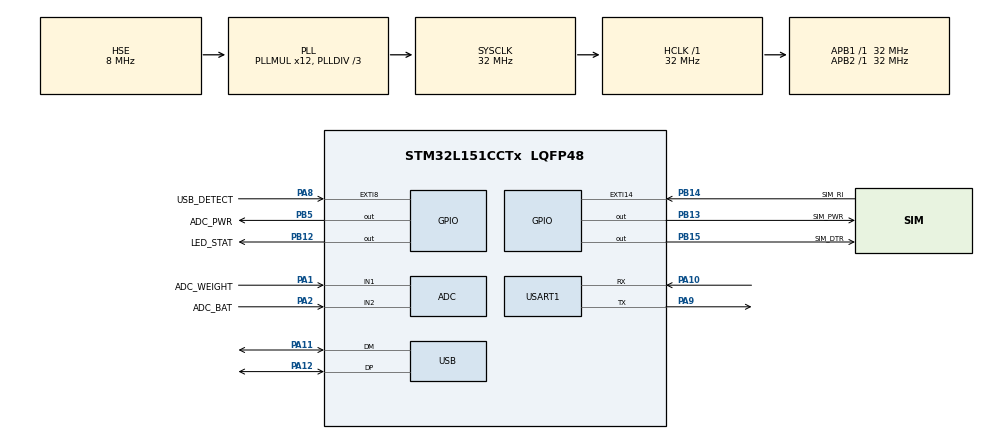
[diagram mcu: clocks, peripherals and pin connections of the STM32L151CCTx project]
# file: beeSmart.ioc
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ADC.Channel-0\#ChannelRegularConversion=ADC_CHANNEL_1
ADC.Channel-1\#ChannelRegularConversion=ADC_CHANNEL_2
ADC.ContinuousConvMode=ENABLE
ADC.NbrOfConversion=2
ADC.NbrOfConversionFlag=1
ADC.Rank-0\#ChannelRegularConversion=1
ADC.Rank-1\#ChannelRegularConversion=2
ADC.SamplingTime-0\#ChannelRegularConversion=ADC_SAMPLETIME_384CYCLES
ADC.SamplingTime-1\#ChannelRegularConversion=ADC_SAMPLETIME_384CYCLES
Dma.ADC.0.Direction=DMA_PERIPH_TO_MEMORY
Dma.ADC.0.Instance=DMA1_Channel1
Dma.ADC.0.MemDataAlignment=DMA_MDATAALIGN_HALFWORD
Dma.ADC.0.MemInc=DMA_MINC_ENABLE
Dma.ADC.0.Mode=DMA_NORMAL
Dma.ADC.0.PeriphDataAlignment=DMA_PDATAALIGN_HALFWORD
Dma.ADC.0.PeriphInc=DMA_PINC_DISABLE
Dma.ADC.0.Priority=DMA_PRIORITY_LOW
Dma.Request0=ADC
FREERTOS.Tasks01=defaultTask,0,128,StartDefaultTask,Default,NULL
Mcu.Family=STM32L1
Mcu.Name=STM32L151CCTx
Mcu.Package=LQFP48
NVIC.ADC1_IRQn=true\:5\:0\:false\:false\:true\:true\:true
NVIC.DMA1_Channel1_IRQn=true\:5\:0\:false\:false\:true\:true\:false
NVIC.EXTI15_10_IRQn=true\:5\:0\:false\:false\:true\:true\:true
NVIC.EXTI9_5_IRQn=true\:5\:0\:false\:false\:true\:true\:true
NVIC.PriorityGroup=NVIC_PRIORITYGROUP_4
NVIC.TIM2_IRQn=true\:0\:0\:false\:false\:true\:false\:false
NVIC.TimeBase=TIM2_IRQn
NVIC.TimeBaseIP=TIM2
NVIC.USART1_IRQn=true\:5\:0\:false\:false\:true\:true\:true
NVIC.USB_LP_IRQn=true\:5\:0\:false\:false\:true\:true\:false
PA1.GPIO_Label=ADC_WEIGHT
PA1.Mode=IN1
PA1.Signal=ADC_IN1
PA10.Mode=Asynchronous
PA10.Signal=USART1_RX
PA11.Mode=Device
PA11.Signal=USB_DM
PA12.Mode=Device
PA12.Signal=USB_DP
PA13.Mode=JTAG_5_pins
PA13.Signal=SYS_JTMS-SWDIO
PA14.Mode=JTAG_5_pins
PA14.Signal=SYS_JTCK-SWCLK
PA15.Mode=JTAG_5_pins
PA15.Signal=SYS_JTDI
PA2.GPIO_Label=ADC_BAT
PA2.Mode=IN2
PA2.Signal=ADC_IN2
PA8.GPIO_Label=USB_DETECT
PA8.Signal=GPXTI8
PA9.Mode=Asynchronous
PA9.Signal=USART1_TX
PB12.GPIO_Label=LED_STAT
PB12.Signal=GPIO_Output
PB13.GPIO_Label=SIM_PWR
PB13.Signal=GPIO_Output
PB14.GPIO_Label=SIM_RI
PB14.Signal=GPXTI14
PB15.GPIO_Label=SIM_DTR
PB15.Signal=GPIO_Output
PB3.Mode=JTAG_5_pins
PB3.Signal=SYS_JTDO-TRACESWO
PB4.Mode=JTAG_5_pins
PB4.Signal=SYS_JTRST
PB5.GPIO_Label=ADC_PWR
PB5.Signal=GPIO_Output
PC14-OSC32_IN.Mode=LSE-External-Oscillator
PC14-OSC32_IN.Signal=RCC_OSC32_IN
PC15-OSC32_OUT.Mode=LSE-External-Oscillator
PC15-OSC32_OUT.Signal=RCC_OSC32_OUT
PH0-OSC_IN.Mode=HSE-External-Oscillator
PH0-OSC_IN.Signal=RCC_OSC_IN
PH1-OSC_OUT.Mode=HSE-External-Oscillator
PH1-OSC_OUT.Signal=RCC_OSC_OUT
ProjectManager.HeapSize=0x200
ProjectManager.StackSize=0x400
ProjectManager.TargetToolchain=SW4STM32
RCC.48MHZClocksFreq_Value=48000000
RCC.AHBFreq_Value=32000000
RCC.APB1Freq_Value=32000000
RCC.APB1TimFreq_Value=32000000
RCC.APB2Freq_Value=32000000
RCC.APB2TimFreq_Value=32000000
RCC.HCLKFreq_Value=32000000
RCC.HSE_VALUE=8000000
RCC.HSI_VALUE=16000000
RCC.MSI_VALUE=2097000
RCC.PLLDIV=RCC_PLL_DIV3
RCC.PLLMUL=RCC_PLL_MUL12
RCC.SYSCLKFreq_VALUE=32000000
RCC.SYSCLKSource=RCC_SYSCLKSOURCE_PLLCLK
RCC.VCOOutputFreq_Value=96000000
USART1.VirtualMode=VM_ASYNC
USB_DEVICE.CLASS_NAME_FS=CDC
USB_DEVICE.VirtualMode=Cdc
USB_DEVICE.VirtualModeFS=Cdc_FS
VP_FREERTOS_VS_ENABLE.Mode=Enabled
VP_RTC_VS_RTC_Activate.Mode=RTC_Enabled
VP_RTC_VS_RTC_Calendar.Mode=RTC_Calendar
VP_RTC_VS_RTC_WakeUp_intern.Mode=WakeUp
VP_SYS_VS_tim2.Mode=TIM2
VP_USB_DEVICE_VS_USB_DEVICE_CDC_FS.Mode=CDC_FS
board=beeSmart

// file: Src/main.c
/**
  ******************************************************************************
  * File Name          : main.c
  * Description        : Main program body
  ******************************************************************************
  * This notice applies to any and all portions of this file
  * that are not between comment pairs USER CODE BEGIN and
  * USER CODE END. Other portions of this file, whether
  * inserted by the user or by software development tools
  * are owned by their respective copyright owners.
  *
  * Copyright (c) 2018 STMicroelectronics International N.V.
  * All rights reserved.
  *
  * Redistribution and use in source and binary forms, with or without
  * modification, are permitted, provided that the following conditions are met:
  *
  * 1. Redistribution of source code must retain the above copyright notice,
  *    this list of conditions and the following disclaimer.
  * 2. Redistributions in binary form must reproduce the above copyright notice,
  *    this list of conditions and the following disclaimer in the documentation
  *    and/or other materials provided with the distribution.
  * 3. Neither the name of STMicroelectronics nor the names of other
  *    contributors to this software may be used to endorse or promote products
  *    derived from this software without specific written permission.
  * 4. This software, including modifications and/or derivative works of this
  *    software, must execute solely and exclusively on microcontroller or
  *    microprocessor devices manufactured by or for STMicroelectronics.
  * 5. Redistribution and use of this software other than as permitted under
  *    this license is void and will automatically terminate your rights under
  *    this license.
  *
  * THIS SOFTWARE IS PROVIDED BY STMICROELECTRONICS AND CONTRIBUTORS "AS IS"
  * AND ANY EXPRESS, IMPLIED OR STATUTORY WARRANTIES, INCLUDING, BUT NOT
  * LIMITED TO, THE IMPLIED WARRANTIES OF MERCHANTABILITY, FITNESS FOR A
  * PARTICULAR PURPOSE AND NON-INFRINGEMENT OF THIRD PARTY INTELLECTUAL PROPERTY
  * RIGHTS ARE DISCLAIMED TO THE FULLEST EXTENT PERMITTED BY LAW. IN NO EVENT
  * SHALL STMICROELECTRONICS OR CONTRIBUTORS BE LIABLE FOR ANY DIRECT, INDIRECT,
  * INCIDENTAL, SPECIAL, EXEMPLARY, OR CONSEQUENTIAL DAMAGES (INCLUDING, BUT NOT
  * LIMITED TO, PROCUREMENT OF SUBSTITUTE GOODS OR SERVICES; LOSS OF USE, DATA,
  * OR PROFITS; OR BUSINESS INTERRUPTION) HOWEVER CAUSED AND ON ANY THEORY OF
  * LIABILITY, WHETHER IN CONTRACT, STRICT LIABILITY, OR TORT (INCLUDING
  * NEGLIGENCE OR OTHERWISE) ARISING IN ANY WAY OUT OF THE USE OF THIS SOFTWARE,
  * EVEN IF ADVISED OF THE POSSIBILITY OF SUCH DAMAGE.
  *
  ******************************************************************************
  */

#include "main.h"
#include "stm32l1xx_hal.h"
#include "cmsis_os.h"
#include "usb_device.h"
#include "communication.h"
#include "sim808.h"

ADC_HandleTypeDef hadc;
DMA_HandleTypeDef hdma_adc;

RTC_HandleTypeDef hrtc;

osThreadId defaultTaskHandle;

/* USER CODE BEGIN PV */
/* Private variables ---------------------------------------------------------*/

/* USER CODE END PV */

void SystemClock_Config(void);
static void MX_GPIO_Init(void);
static void MX_DMA_Init(void);
static void MX_RTC_Init(void);
static void MX_ADC_Init(void);
void StartDefaultTask(void const * argument);

/* USER CODE BEGIN PFP */
/* Private function prototypes -----------------------------------------------*/

/* USER CODE END PFP */

int main(void)
{

  /* MCU Configuration----------------------------------------------------------*/

  /* Reset of all peripherals, Initializes the Flash interface and the Systick. */
  HAL_Init();

  /* Configure the system clock */
  SystemClock_Config();

  /* Initialize all configured peripherals */
  MX_GPIO_Init();
  MX_DMA_Init();
  MX_RTC_Init();
  MX_USART1_UART_Init();
  MX_ADC_Init();

  /* Create the thread(s) */
  /* definition and creation of defaultTask */
  osThreadDef(defaultTask, StartDefaultTask, osPriorityNormal, 0, 128);
  defaultTaskHandle = osThreadCreate(osThread(defaultTask), NULL);

  /* Start scheduler */
  osKernelStart();

  /* We should never get here as control is now taken by the scheduler */

  /* Infinite loop */
  while (1)
  {

  }

}

/** System Clock Configuration
*/
void SystemClock_Config(void)
{

  RCC_OscInitTypeDef RCC_OscInitStruct;
  RCC_ClkInitTypeDef RCC_ClkInitStruct;
  RCC_PeriphCLKInitTypeDef PeriphClkInit;

    /**Configure the main internal regulator output voltage
    */
  __HAL_PWR_VOLTAGESCALING_CONFIG(PWR_REGULATOR_VOLTAGE_SCALE1);

    /**Initializes the CPU, AHB and APB busses clocks
    */
  RCC_OscInitStruct.OscillatorType = RCC_OSCILLATORTYPE_HSI|RCC_OSCILLATORTYPE_LSI
                              |RCC_OSCILLATORTYPE_HSE;
  RCC_OscInitStruct.HSEState = RCC_HSE_ON;
  RCC_OscInitStruct.HSIState = RCC_HSI_ON;
  RCC_OscInitStruct.HSICalibrationValue = 16;
  RCC_OscInitStruct.LSIState = RCC_LSI_ON;
  RCC_OscInitStruct.PLL.PLLState = RCC_PLL_ON;
  RCC_OscInitStruct.PLL.PLLSource = RCC_PLLSOURCE_HSE;
  RCC_OscInitStruct.PLL.PLLMUL = RCC_PLL_MUL12;
  RCC_OscInitStruct.PLL.PLLDIV = RCC_PLL_DIV3;
  if (HAL_RCC_OscConfig(&RCC_OscInitStruct) != HAL_OK)
  {
    _Error_Handler(__FILE__, __LINE__);
  }

    /**Initializes the CPU, AHB and APB busses clocks
    */
  RCC_ClkInitStruct.ClockType = RCC_CLOCKTYPE_HCLK|RCC_CLOCKTYPE_SYSCLK
                              |RCC_CLOCKTYPE_PCLK1|RCC_CLOCKTYPE_PCLK2;
  RCC_ClkInitStruct.SYSCLKSource = RCC_SYSCLKSOURCE_PLLCLK;
  RCC_ClkInitStruct.AHBCLKDivider = RCC_SYSCLK_DIV1;
  RCC_ClkInitStruct.APB1CLKDivider = RCC_HCLK_DIV1;
  RCC_ClkInitStruct.APB2CLKDivider = RCC_HCLK_DIV1;

  if (HAL_RCC_ClockConfig(&RCC_ClkInitStruct, FLASH_LATENCY_1) != HAL_OK)
  {
    _Error_Handler(__FILE__, __LINE__);
  }

  PeriphClkInit.PeriphClockSelection = RCC_PERIPHCLK_RTC;
  PeriphClkInit.RTCClockSelection = RCC_RTCCLKSOURCE_LSI;
  if (HAL_RCCEx_PeriphCLKConfig(&PeriphClkInit) != HAL_OK)
  {
    _Error_Handler(__FILE__, __LINE__);
  }

    /**Configure the Systick interrupt time
    */
  HAL_SYSTICK_Config(HAL_RCC_GetHCLKFreq()/1000);

    /**Configure the Systick
    */
  HAL_SYSTICK_CLKSourceConfig(SYSTICK_CLKSOURCE_HCLK);

  /* SysTick_IRQn interrupt configuration */
  HAL_NVIC_SetPriority(SysTick_IRQn, 15, 0);
}

/* ADC init function */
static void MX_ADC_Init(void)
{

  ADC_ChannelConfTypeDef sConfig;

    /**Configure the global features of the ADC (Clock, Resolution, Data Alignment and number of conversion)
    */
  hadc.Instance = ADC1;
  hadc.Init.ClockPrescaler = ADC_CLOCK_ASYNC_DIV1;
  hadc.Init.Resolution = ADC_RESOLUTION_12B;
  hadc.Init.DataAlign = ADC_DATAALIGN_RIGHT;
  hadc.Init.ScanConvMode = ADC_SCAN_DISABLE;
  hadc.Init.EOCSelection = ADC_EOC_SEQ_CONV;
  hadc.Init.LowPowerAutoWait = ADC_AUTOWAIT_DISABLE;
  hadc.Init.LowPowerAutoPowerOff = ADC_AUTOPOWEROFF_DISABLE;
  hadc.Init.ChannelsBank = ADC_CHANNELS_BANK_A;
  hadc.Init.ContinuousConvMode = ENABLE;
  hadc.Init.NbrOfConversion = 2;
  hadc.Init.DiscontinuousConvMode = DISABLE;
  hadc.Init.ExternalTrigConv = ADC_SOFTWARE_START;
  hadc.Init.ExternalTrigConvEdge = ADC_EXTERNALTRIGCONVEDGE_NONE;
  hadc.Init.DMAContinuousRequests = DISABLE;
  if (HAL_ADC_Init(&hadc) != HAL_OK)
  {
    _Error_Handler(__FILE__, __LINE__);
  }

    /**Configure for the selected ADC regular channel its corresponding rank in the sequencer and its sample time.
    */
  sConfig.Channel = ADC_CHANNEL_1;
  sConfig.Rank = 1;
  sConfig.SamplingTime = ADC_SAMPLETIME_384CYCLES;
  if (HAL_ADC_ConfigChannel(&hadc, &sConfig) != HAL_OK)
  {
    _Error_Handler(__FILE__, __LINE__);
  }

    /**Configure for the selected ADC regular channel its corresponding rank in the sequencer and its sample time.
    */
  sConfig.Channel = ADC_CHANNEL_2;
  sConfig.Rank = 2;
  if (HAL_ADC_ConfigChannel(&hadc, &sConfig) != HAL_OK)
  {
    _Error_Handler(__FILE__, __LINE__);
  }

}

/* RTC init function */
static void MX_RTC_Init(void)
{

  RTC_TimeTypeDef sTime;
  RTC_DateTypeDef sDate;

    /**Initialize RTC Only
    */
  hrtc.Instance = RTC;
  hrtc.Init.HourFormat = RTC_HOURFORMAT_24;
  hrtc.Init.AsynchPrediv = 127;
  hrtc.Init.SynchPrediv = 255;
  hrtc.Init.OutPut = RTC_OUTPUT_DISABLE;
  hrtc.Init.OutPutPolarity = RTC_OUTPUT_POLARITY_HIGH;
  hrtc.Init.OutPutType = RTC_OUTPUT_TYPE_OPENDRAIN;
  if (HAL_RTC_Init(&hrtc) != HAL_OK)
  {
    _Error_Handler(__FILE__, __LINE__);
  }

    /**Initialize RTC and set the Time and Date
    */
  if(HAL_RTCEx_BKUPRead(&hrtc, RTC_BKP_DR0) != 0x32F2){
  sTime.Hours = 0x0;
  sTime.Minutes = 0x0;
  sTime.Seconds = 0x0;
  sTime.DayLightSaving = RTC_DAYLIGHTSAVING_NONE;
  sTime.StoreOperation = RTC_STOREOPERATION_RESET;
  if (HAL_RTC_SetTime(&hrtc, &sTime, RTC_FORMAT_BCD) != HAL_OK)
  {
    _Error_Handler(__FILE__, __LINE__);
  }

  sDate.WeekDay = RTC_WEEKDAY_MONDAY;
  sDate.Month = RTC_MONTH_JANUARY;
  sDate.Date = 0x1;
  sDate.Year = 0x0;

  if (HAL_RTC_SetDate(&hrtc, &sDate, RTC_FORMAT_BCD) != HAL_OK)
  {
    _Error_Handler(__FILE__, __LINE__);
  }

    HAL_RTCEx_BKUPWrite(&hrtc,RTC_BKP_DR0,0x32F2);
  }
    /**Enable the WakeUp
    */
  if (HAL_RTCEx_SetWakeUpTimer(&hrtc, 0, RTC_WAKEUPCLOCK_RTCCLK_DIV16) != HAL_OK)
  {
    _Error_Handler(__FILE__, __LINE__);
  }

}

static void MX_DMA_Init(void)
{
  /* DMA controller clock enable */
  __HAL_RCC_DMA1_CLK_ENABLE();

  /* DMA interrupt init */
  /* DMA1_Channel1_IRQn interrupt configuration */
  HAL_NVIC_SetPriority(DMA1_Channel1_IRQn, 5, 0);
  HAL_NVIC_EnableIRQ(DMA1_Channel1_IRQn);

}

/** Configure pins as
        * Analog
        * Input
        * Output
        * EVENT_OUT
        * EXTI
*/
static void MX_GPIO_Init(void)
{

  GPIO_InitTypeDef GPIO_InitStruct;

  /* GPIO Ports Clock Enable */
  __HAL_RCC_GPIOC_CLK_ENABLE();
  __HAL_RCC_GPIOH_CLK_ENABLE();
  __HAL_RCC_GPIOA_CLK_ENABLE();
  __HAL_RCC_GPIOB_CLK_ENABLE();

  /*Configure GPIO pin Output Level */
  HAL_GPIO_WritePin(GPIOB, LED_STAT_Pin|SIM_PWR_Pin|SIM_DTR_Pin|ADC_PWR_Pin, GPIO_PIN_RESET);

  /*Configure GPIO pins : LED_STAT_Pin SIM_PWR_Pin SIM_DTR_Pin ADC_PWR_Pin */
  GPIO_InitStruct.Pin = LED_STAT_Pin|SIM_PWR_Pin|SIM_DTR_Pin|ADC_PWR_Pin;
  GPIO_InitStruct.Mode = GPIO_MODE_OUTPUT_PP;
  GPIO_InitStruct.Pull = GPIO_NOPULL;
  GPIO_InitStruct.Speed = GPIO_SPEED_FREQ_LOW;
  HAL_GPIO_Init(GPIOB, &GPIO_InitStruct);

  /*Configure GPIO pin : SIM_RI_Pin */
  GPIO_InitStruct.Pin = SIM_RI_Pin;
  GPIO_InitStruct.Mode = GPIO_MODE_IT_RISING;
  GPIO_InitStruct.Pull = GPIO_NOPULL;
  HAL_GPIO_Init(SIM_RI_GPIO_Port, &GPIO_InitStruct);

  /*Configure GPIO pin : USB_DETECT_Pin */
  GPIO_InitStruct.Pin = USB_DETECT_Pin;
  GPIO_InitStruct.Mode = GPIO_MODE_IT_RISING;
  GPIO_InitStruct.Pull = GPIO_NOPULL;
  HAL_GPIO_Init(USB_DETECT_GPIO_Port, &GPIO_InitStruct);

  /* EXTI interrupt init*/
  HAL_NVIC_SetPriority(EXTI9_5_IRQn, 5, 0);
  HAL_NVIC_EnableIRQ(EXTI9_5_IRQn);

  HAL_NVIC_SetPriority(EXTI15_10_IRQn, 5, 0);
  HAL_NVIC_EnableIRQ(EXTI15_10_IRQn);

}

/* StartDefaultTask function */
void StartDefaultTask(void const * argument)
{
  /* init code for USB_DEVICE */
	//char *buf = NULL;
	//sprintf(buf, "Hello World!%c", (char )26);
  MX_USB_DEVICE_Init();
  communicationInit();
  sim808_rx_uartInit();
  HAL_GPIO_WritePin(SIM_PWR_GPIO_Port, SIM_PWR_Pin, GPIO_PIN_SET);
  vTaskDelay(1500);
  HAL_GPIO_WritePin(SIM_PWR_GPIO_Port, SIM_PWR_Pin, GPIO_PIN_RESET);
  vTaskDelay(10000);
  sim808_sendMsg("AT+CMGF=1\r");
  //sim808_sendMsg("ATD00385923300424;\r");
  vTaskDelay(1000);
  sim808_sendMsg("AT+CMGS=\"00385923300424\"");
  vTaskDelay(1000);
  sim808_sendMsg("Hello World!");
  vTaskDelay(100);
  sim808_sendMsg((char*)26);
  //uint8_t *message = "Hello\r\n";

  /* USER CODE BEGIN 5 */
  /* Infinite loop */
  for(;;)
  {
	  //CDC_Transmit_FS(message, 10);

    vTaskDelay(1000);
  }
  /* USER CODE END 5 */
}

void HAL_TIM_PeriodElapsedCallback(TIM_HandleTypeDef *htim)
{
  if (htim->Instance == TIM2) {
    HAL_IncTick();
  }
}

void _Error_Handler(char * file, int line)
{
  while(1)
  {
  }
}

/************************ (C) COPYRIGHT STMicroelectronics *****END OF FILE****/
